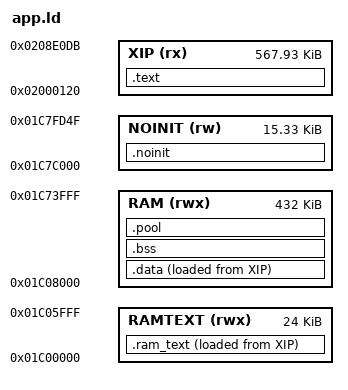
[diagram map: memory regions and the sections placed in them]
/* SPDX-License-Identifier: GPL-3.0-only
 * Copyright (C) 2026 Leo Kuroshita (@kurogedelic), Hügelton Instruments */
/* FM-1 OPL3 TRACKER memory map (after Felucca's).
 * Code + constants execute in place from XIP (app.bin offset 0 = 0x02000120).
 * 0x01C00000..0x01C06000 holds .ram_text (code that must run while the flash
 * is busy: the flash driver); 0x01C06000..0x01C08000 stays for RAM-run debug.
 * RAM  : .data, .bss and .pool, then the HEAP up to the stack guard (malloc, compat/fm1_libc.c: the
 *        tracker's module, its FM macros, the file buffers). tools/build.py reports what is left.
 * STACKS with 256-byte guard bands; NOINIT survives resets and UBOOT entry.
 * 0x01C7FD50.. is reserved: boot_info, boot-state mailbox, vector table. */
MEMORY
{
    XIP    (rx)  : ORIGIN = 0x02000120, LENGTH = 0x8DFBC
    RAMTEXT (rwx): ORIGIN = 0x01C00000, LENGTH = 0x6000
    RAM    (rwx) : ORIGIN = 0x01C08000, LENGTH = 0x6C000
    NOINIT (rw)  : ORIGIN = 0x01C7C000, LENGTH = 0x3D50
}
SECTIONS
{
    .text : {
        KEEP(*(.text.crt0)) *(.text*) *(.rodata*)
        . = ALIGN(4);
        __init_array_start = .; KEEP(*(SORT(.init_array.*))) KEEP(*(.init_array)) KEEP(*(.ctors)) __init_array_end = .;
        . = ALIGN(4); _etext = .;
    } > XIP
    .ram_text : { _rt_start = .; KEEP(*(.ram_text*)) . = ALIGN(4); _rt_end = .; } > RAMTEXT AT > XIP
    _rt_load = LOADADDR(.ram_text);
    .data : { . = ALIGN(4); _data_start = .; *(.data*) *(.sdata*) . = ALIGN(4); _data_end = .; } > RAM AT > XIP
    _data_load = LOADADDR(.data);
    .bss (NOLOAD) : { _bss_start = .; *(.bss*) *(.sbss*) *(COMMON) . = ALIGN(4); _bss_end = .; } > RAM
    .pool (NOLOAD) : { _pool_start = .; *(.pool*) . = ALIGN(4); _pool_end = .; } > RAM
    _heap_start = ALIGN(_pool_end, 8);
    _heap_end = 0x01C74000;
    .noinit (NOLOAD) : { *(.noinit*) } > NOINIT
    _guard0 = 0x01C74000; _ustack_lo = 0x01C74100; _ustack_top = 0x01C7A000;
    _guard1 = 0x01C7A000; _sstack_lo = 0x01C7A100; _sstack_top = 0x01C7C000;
    /DISCARD/ : { *(.comment) *(.note*) *(.ARM.exidx*) *(.eh_frame*) }
}
